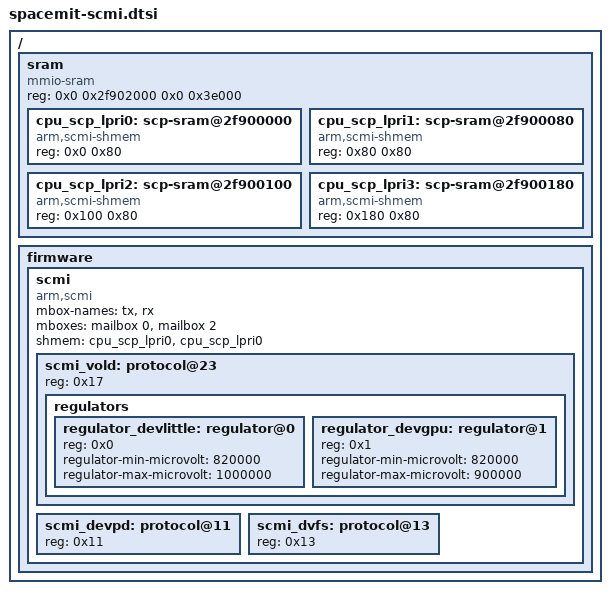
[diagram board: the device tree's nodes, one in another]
/ {
	sram {
		compatible = "mmio-sram";
		/* 256k */
		reg = <0x0 0x2f902000 0x0 0x3e000>;
		#address-cells = <1>;
		#size-cells = <1>;
		ranges = <0x0 0x0 0x2f902000 0x3e000>;

		/* channel 0*/
		cpu_scp_lpri0: scp-sram@2f900000 {
			compatible = "arm,scmi-shmem";
			reg = <0x0 0x80>;
		};

		/* channel 1*/
		cpu_scp_lpri1: scp-sram@2f900080 {
			compatible = "arm,scmi-shmem";
			reg = <0x80 0x80>;
		};

		/* channel 2*/
		cpu_scp_lpri2: scp-sram@2f900100 {
			compatible = "arm,scmi-shmem";
			reg = <0x100 0x80>;
		};

		/* channel 3*/
		cpu_scp_lpri3: scp-sram@2f900180 {
			compatible = "arm,scmi-shmem";
			reg = <0x180 0x80>;
		};
	};

	firmware {
		scmi {
			compatible = "arm,scmi";
			mbox-names = "tx", "rx";
			mboxes = <&mailbox 0 &mailbox 2>;
			shmem = <&cpu_scp_lpri0 &cpu_scp_lpri0>;
			#address-cells = <1>;
			#size-cells = <0>;

			scmi_vold: protocol@23 {
				reg = <0x17>;
				regulators {
					#address-cells = <1>;
					#size-cells = <0>;

					regulator_devlittle: regulator@0 {
						reg = <0x0>;
						regulator-min-microvolt = <820000>;
						regulator-max-microvolt = <1000000>;
					};

					regulator_devgpu: regulator@1 {
						reg = <0x1>;
						regulator-min-microvolt = <820000>;
						regulator-max-microvolt = <900000>;
					};
				};
			};

			scmi_devpd: protocol@11 {
				reg = <0x11>;
				#power-domain-cells = <1>;
			};

			scmi_dvfs: protocol@13 {
				reg = <0x13>;
				#clock-cells = <1>;
			};
		};
	};
};

